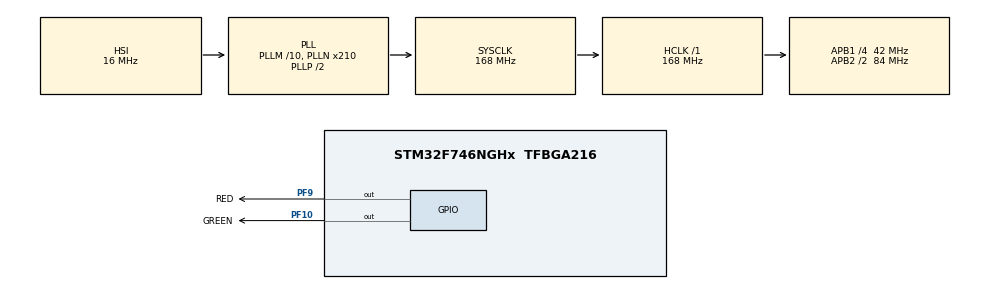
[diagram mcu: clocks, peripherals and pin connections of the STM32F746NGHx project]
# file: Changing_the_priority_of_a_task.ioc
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FREERTOS.Tasks01=defaultTask,0,128,StartDefaultTask,Default,NULL,Dynamic,NULL,NULL;Calculate,0,128,StartCalculate,Default,NULL,Dynamic,NULL,NULL;RedToggle,2,128,StartRedToggle,Default,NULL,Dynamic,NULL,NULL;GreenToggle,-2,128,StartGreenToggle,Default,NULL,Dynamic,NULL,NULL
Mcu.Family=STM32F7
Mcu.Name=STM32F746NGHx
Mcu.Package=TFBGA216
NVIC.PriorityGroup=NVIC_PRIORITYGROUP_4
NVIC.TIM8_TRG_COM_TIM14_IRQn=true\:0\:0\:false\:false\:true\:false\:false\:true
NVIC.TimeBase=TIM8_TRG_COM_TIM14_IRQn
NVIC.TimeBaseIP=TIM14
PA13.Mode=Serial_Wire
PA13.Signal=SYS_JTMS-SWDIO
PA14.Mode=Serial_Wire
PA14.Signal=SYS_JTCK-SWCLK
PC14/OSC32_IN.Mode=LSE-External-Clock-Source
PC14/OSC32_IN.Signal=RCC_OSC32_IN
PC15/OSC32_OUT.Mode=LSE-External-Clock-Source
PC15/OSC32_OUT.Signal=RCC_OSC32_OUT
PF10.GPIO_Label=GREEN
PF10.Signal=GPIO_Output
PF9.GPIO_Label=RED
PF9.Signal=GPIO_Output
PH0/OSC_IN.Mode=HSE-External-Oscillator
PH0/OSC_IN.Signal=RCC_OSC_IN
PH1/OSC_OUT.Mode=HSE-External-Oscillator
PH1/OSC_OUT.Signal=RCC_OSC_OUT
ProjectManager.HeapSize=0x200
ProjectManager.StackSize=0x400
ProjectManager.TargetToolchain=STM32CubeIDE
RCC.AHBFreq_Value=168000000
RCC.APB1CLKDivider=RCC_HCLK_DIV4
RCC.APB1Freq_Value=42000000
RCC.APB1TimFreq_Value=84000000
RCC.APB2CLKDivider=RCC_HCLK_DIV2
RCC.APB2Freq_Value=84000000
RCC.APB2TimFreq_Value=168000000
RCC.CortexFreq_Value=168000000
RCC.HCLKFreq_Value=168000000
RCC.HSE_VALUE=25000000
RCC.HSI_VALUE=16000000
RCC.LSE_VALUE=32768
RCC.PLLM=10
RCC.PLLN=210
RCC.PLLSourceVirtual=RCC_PLLSOURCE_HSI
RCC.SYSCLKFreq_VALUE=168000000
RCC.SYSCLKSource=RCC_SYSCLKSOURCE_PLLCLK
RCC.USBFreq_Value=168000000
RCC.VCOOutputFreq_Value=336000000
VP_FREERTOS_VS_CMSIS_V1.Mode=CMSIS_V1
VP_SYS_VS_tim14.Mode=TIM14
board=STM32F746G-DISCO

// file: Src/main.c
/* USER CODE BEGIN Header */
/**
 ******************************************************************************
 * @file           : main.c
 * @brief          : Main program body
 ******************************************************************************
 * @attention
 *
 * <h2><center>&copy; Copyright (c) 2019 STMicroelectronics.
 * All rights reserved.</center></h2>
 *
 * This software component is licensed by ST under BSD 3-Clause license,
 * the "License"; You may not use this file except in compliance with the
 * License. You may obtain a copy of the License at:
 *                        opensource.org/licenses/BSD-3-Clause
 *
 ******************************************************************************
 */
/* USER CODE END Header */

#include "main.h"
#include "cmsis_os.h"

osThreadId defaultTaskHandle;
osThreadId CalculateHandle;
osThreadId RedToggleHandle;
osThreadId GreenToggleHandle;

void SystemClock_Config(void);
static void MX_GPIO_Init(void);
void StartDefaultTask(void const * argument);
void StartCalculate(void const * argument);
void StartRedToggle(void const * argument);
void StartGreenToggle(void const * argument);

int main(void)
{

  /* MCU Configuration--------------------------------------------------------*/

  /* Reset of all peripherals, Initializes the Flash interface and the Systick. */
  HAL_Init();

  /* Configure the system clock */
  SystemClock_Config();

  /* Initialize all configured peripherals */
  MX_GPIO_Init();

  /* Create the thread(s) */
  /* definition and creation of defaultTask */
  osThreadDef(defaultTask, StartDefaultTask, osPriorityNormal, 0, 128);
  defaultTaskHandle = osThreadCreate(osThread(defaultTask), NULL);

  /* definition and creation of Calculate */
  osThreadDef(Calculate, StartCalculate, osPriorityNormal, 0, 128);
  CalculateHandle = osThreadCreate(osThread(Calculate), NULL);

  /* definition and creation of RedToggle */
  osThreadDef(RedToggle, StartRedToggle, osPriorityHigh, 0, 128);
  RedToggleHandle = osThreadCreate(osThread(RedToggle), NULL);

  /* definition and creation of GreenToggle */
  osThreadDef(GreenToggle, StartGreenToggle, osPriorityLow, 0, 128);
  GreenToggleHandle = osThreadCreate(osThread(GreenToggle), NULL);

  /* Start scheduler */
  osKernelStart();

  /* We should never get here as control is now taken by the scheduler */

  /* Infinite loop */
	while (1) {

	}
}

void SystemClock_Config(void)
{
  RCC_OscInitTypeDef RCC_OscInitStruct = {0};
  RCC_ClkInitTypeDef RCC_ClkInitStruct = {0};

  /** Configure the main internal regulator output voltage
  */
  __HAL_RCC_PWR_CLK_ENABLE();
  __HAL_PWR_VOLTAGESCALING_CONFIG(PWR_REGULATOR_VOLTAGE_SCALE2);
  /** Initializes the CPU, AHB and APB busses clocks
  */
  RCC_OscInitStruct.OscillatorType = RCC_OSCILLATORTYPE_HSI;
  RCC_OscInitStruct.HSIState = RCC_HSI_ON;
  RCC_OscInitStruct.HSICalibrationValue = RCC_HSICALIBRATION_DEFAULT;
  RCC_OscInitStruct.PLL.PLLState = RCC_PLL_ON;
  RCC_OscInitStruct.PLL.PLLSource = RCC_PLLSOURCE_HSI;
  RCC_OscInitStruct.PLL.PLLM = 10;
  RCC_OscInitStruct.PLL.PLLN = 210;
  RCC_OscInitStruct.PLL.PLLP = RCC_PLLP_DIV2;
  RCC_OscInitStruct.PLL.PLLQ = 2;
  if (HAL_RCC_OscConfig(&RCC_OscInitStruct) != HAL_OK)
  {
    Error_Handler();
  }
  /** Initializes the CPU, AHB and APB busses clocks
  */
  RCC_ClkInitStruct.ClockType = RCC_CLOCKTYPE_HCLK|RCC_CLOCKTYPE_SYSCLK
                              |RCC_CLOCKTYPE_PCLK1|RCC_CLOCKTYPE_PCLK2;
  RCC_ClkInitStruct.SYSCLKSource = RCC_SYSCLKSOURCE_PLLCLK;
  RCC_ClkInitStruct.AHBCLKDivider = RCC_SYSCLK_DIV1;
  RCC_ClkInitStruct.APB1CLKDivider = RCC_HCLK_DIV4;
  RCC_ClkInitStruct.APB2CLKDivider = RCC_HCLK_DIV2;

  if (HAL_RCC_ClockConfig(&RCC_ClkInitStruct, FLASH_LATENCY_5) != HAL_OK)
  {
    Error_Handler();
  }
}

static void MX_GPIO_Init(void)
{
  GPIO_InitTypeDef GPIO_InitStruct = {0};

  /* GPIO Ports Clock Enable */
  __HAL_RCC_GPIOA_CLK_ENABLE();
  __HAL_RCC_GPIOC_CLK_ENABLE();
  __HAL_RCC_GPIOH_CLK_ENABLE();
  __HAL_RCC_GPIOF_CLK_ENABLE();

  /*Configure GPIO pin Output Level */
  HAL_GPIO_WritePin(GPIOF, GREEN_Pin|RED_Pin, GPIO_PIN_RESET);

  /*Configure GPIO pins : GREEN_Pin RED_Pin */
  GPIO_InitStruct.Pin = GREEN_Pin|RED_Pin;
  GPIO_InitStruct.Mode = GPIO_MODE_OUTPUT_PP;
  GPIO_InitStruct.Pull = GPIO_NOPULL;
  GPIO_InitStruct.Speed = GPIO_SPEED_FREQ_LOW;
  HAL_GPIO_Init(GPIOF, &GPIO_InitStruct);

}

void StartDefaultTask(void const * argument)
{

	for (;;) {
		osDelay(1);
	}
}

void StartCalculate(void const * argument)
{
  /* USER CODE BEGIN StartCalculate */
	/* Infinite loop */
	for (;;) {
int number = 0;
int other_number = 0;
		while(1){
			if(number % 2  == 0){
				other_number = number;
				number++;
			}

		}
	}
  /* USER CODE END StartCalculate */
}

void StartRedToggle(void const * argument)
{
  /* USER CODE BEGIN StartRedToggle */
	/* Infinite loop */
	for (;;) {
		HAL_GPIO_TogglePin(RED_GPIO_Port, RED_Pin);
		osDelay(500);
		osDelay(1);
	}
  /* USER CODE END StartRedToggle */
}

void StartGreenToggle(void const * argument)
{
  /* USER CODE BEGIN StartGreenToggle */
	/* Infinite loop */
	for (;;) {

		HAL_GPIO_TogglePin(GREEN_GPIO_Port, GREEN_Pin);
		osDelay(500);

		osDelay(1);
	}
  /* USER CODE END StartGreenToggle */
}

void HAL_TIM_PeriodElapsedCallback(TIM_HandleTypeDef *htim)
{
  if (htim->Instance == TIM14) {
    HAL_IncTick();
  }
}

void Error_Handler(void)
{
}

/************************ (C) COPYRIGHT STMicroelectronics *****END OF FILE****/
